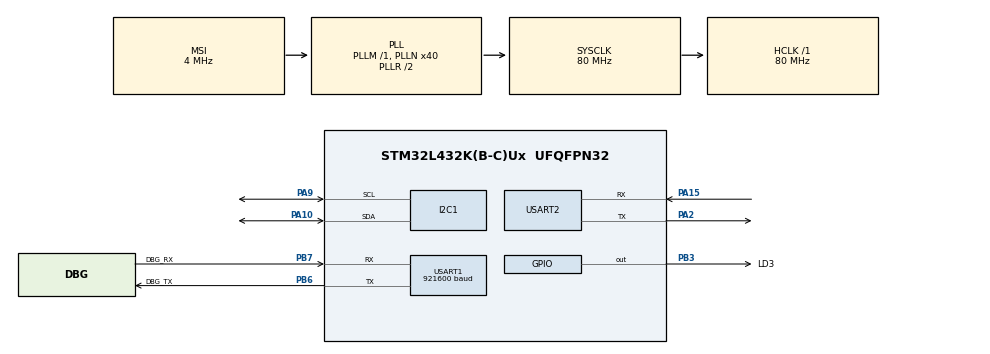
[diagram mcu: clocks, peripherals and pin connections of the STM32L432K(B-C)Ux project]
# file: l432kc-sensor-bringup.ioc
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FREERTOS.Mutexes01=i2c1_mutex,Dynamic,NULL,Available;console_mutex,Dynamic,NULL,Available
FREERTOS.Tasks01=sensorTask,24,512,StartSensorTask,Default,NULL,Dynamic,NULL,NULL;consoleTask,16,256,StartConsoleTask,Default,NULL,Dynamic,NULL,NULL
FREERTOS.configTOTAL_HEAP_SIZE=32768
FREERTOS.configUSE_NEWLIB_REENTRANT=1
I2C1.Timing=0x10909CEC
Mcu.Family=STM32L4
Mcu.Name=STM32L432K(B-C)Ux
Mcu.Package=UFQFPN32
NVIC.I2C1_ER_IRQn=true\:5\:0\:false\:false\:true\:true\:true\:true
NVIC.I2C1_EV_IRQn=true\:5\:0\:false\:false\:true\:true\:true\:true
NVIC.PriorityGroup=NVIC_PRIORITYGROUP_4
NVIC.USART1_IRQn=true\:5\:0\:false\:false\:true\:true\:true\:true
NVIC.USART2_IRQn=true\:5\:0\:false\:false\:true\:true\:true\:true
PA10.Mode=I2C
PA10.Signal=I2C1_SDA
PA15\ (JTDI).Mode=Asynchronous
PA15\ (JTDI).Signal=USART2_RX
PA2.Mode=Asynchronous
PA2.Signal=USART2_TX
PA9.Mode=I2C
PA9.Signal=I2C1_SCL
PB3\ (JTDO-TRACESWO).GPIO_Label=LD3
PB3\ (JTDO-TRACESWO).Signal=GPIO_Output
PB6.GPIO_Label=DBG_TX
PB6.Mode=Asynchronous
PB6.Signal=USART1_TX
PB7.GPIO_Label=DBG_RX
PB7.GPIO_PuPd=GPIO_PULLUP
PB7.Mode=Asynchronous
PB7.Signal=USART1_RX
PC14-OSC32_IN\ (PC14).Mode=LSE-External-Oscillator
PC14-OSC32_IN\ (PC14).Signal=RCC_OSC32_IN
PC15-OSC32_OUT\ (PC15).Mode=LSE-External-Oscillator
PC15-OSC32_OUT\ (PC15).Signal=RCC_OSC32_OUT
ProjectManager.HeapSize=0x200
ProjectManager.StackSize=0x400
ProjectManager.TargetToolchain=STM32CubeIDE
RCC.FLatency=FLASH_LATENCY_4
RCC.HCLKFreq_Value=80000000
RCC.HSE_VALUE=8000000
RCC.HSI48_VALUE=48000000
RCC.HSI_VALUE=16000000
RCC.LSE_VALUE=32768
RCC.MSIPLLMode=RCC_MSIPLL_ENABLE
RCC.MSI_VALUE=4000000
RCC.PLLN=40
RCC.PLLSourceVirtual=RCC_PLLSOURCE_MSI
RCC.SYSCLKFreq_VALUE=80000000
RCC.SYSCLKSource=RCC_SYSCLKSOURCE_PLLCLK
RCC.VCOOutputFreq_Value=32000000
USART1.BaudRate=921600
USART1.VirtualMode-Asynchronous=VM_ASYNC
USART2.VirtualMode-Asynchronous=VM_ASYNC
VP_FREERTOS_VS_CMSIS_V2.Mode=CMSIS_V2
board=custom

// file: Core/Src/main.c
/* USER CODE BEGIN Header */
/**
  ******************************************************************************
  * @file           : main.c
  * @brief          : Main program body
  *
  *  The application (BMP390 and SHT31 bring-up) is in app.cpp; this file
  *  stays CubeMX's, and its USER CODE blocks only call into app.h.
  ******************************************************************************
  * @attention
  *
  * Copyright (c) 2026 STMicroelectronics.
  * All rights reserved.
  *
  * This software is licensed under terms that can be found in the LICENSE file
  * in the root directory of this software component.
  * If no LICENSE file comes with this software, it is provided AS-IS.
  *
  ******************************************************************************
  */
/* USER CODE END Header */
#include "main.h"
#include "cmsis_os.h"

/* USER CODE BEGIN Includes */
#include "app.h"
/* USER CODE END Includes */

I2C_HandleTypeDef hi2c1;

UART_HandleTypeDef huart1;
UART_HandleTypeDef huart2;

/* Definitions for sensorTask */
osThreadId_t sensorTaskHandle;
const osThreadAttr_t sensorTask_attributes = {
  .name = "sensorTask",
  .stack_size = 512 * 4,
  .priority = (osPriority_t) osPriorityNormal,
};
/* Definitions for consoleTask */
osThreadId_t consoleTaskHandle;
const osThreadAttr_t consoleTask_attributes = {
  .name = "consoleTask",
  .stack_size = 256 * 4,
  .priority = (osPriority_t) osPriorityBelowNormal,
};
/* Definitions for i2c1_mutex */
osMutexId_t i2c1_mutexHandle;
const osMutexAttr_t i2c1_mutex_attributes = {
  .name = "i2c1_mutex"
};
/* Definitions for console_mutex */
osMutexId_t console_mutexHandle;
const osMutexAttr_t console_mutex_attributes = {
  .name = "console_mutex"
};

void SystemClock_Config(void);
static void MX_GPIO_Init(void);
static void MX_I2C1_Init(void);
static void MX_USART1_UART_Init(void);
static void MX_USART2_UART_Init(void);
void StartSensorTask(void *argument);
void StartConsoleTask(void *argument);

int main(void)
{

  /* MCU Configuration--------------------------------------------------------*/

  /* Reset of all peripherals, Initializes the Flash interface and the Systick. */
  HAL_Init();

  /* Configure the system clock */
  SystemClock_Config();

  /* Initialize all configured peripherals */
  MX_GPIO_Init();
  MX_I2C1_Init();
  MX_USART1_UART_Init();
  MX_USART2_UART_Init();
  /* USER CODE BEGIN 2 */
  app_init();
  /* USER CODE END 2 */

  /* Init scheduler */
  osKernelInitialize();
  /* Create the mutex(es) */
  /* creation of i2c1_mutex */
  i2c1_mutexHandle = osMutexNew(&i2c1_mutex_attributes);

  /* creation of console_mutex */
  console_mutexHandle = osMutexNew(&console_mutex_attributes);

  /* Create the thread(s) */
  /* creation of sensorTask */
  sensorTaskHandle = osThreadNew(StartSensorTask, NULL, &sensorTask_attributes);

  /* creation of consoleTask */
  consoleTaskHandle = osThreadNew(StartConsoleTask, NULL, &consoleTask_attributes);

  /* Start scheduler */
  osKernelStart();

  /* We should never get here as control is now taken by the scheduler */

  /* Infinite loop */
  while (1)
  {

  }
}

void SystemClock_Config(void)
{
  RCC_OscInitTypeDef RCC_OscInitStruct = {0};
  RCC_ClkInitTypeDef RCC_ClkInitStruct = {0};

  /** Configure the main internal regulator output voltage
  */
  if (HAL_PWREx_ControlVoltageScaling(PWR_REGULATOR_VOLTAGE_SCALE1) != HAL_OK)
  {
    Error_Handler();
  }

  /** Configure LSE Drive Capability
  */
  HAL_PWR_EnableBkUpAccess();
  __HAL_RCC_LSEDRIVE_CONFIG(RCC_LSEDRIVE_LOW);

  /** Initializes the RCC Oscillators according to the specified parameters
  * in the RCC_OscInitTypeDef structure.
  * MSI 4 MHz -> PLL x40 /2 -> 80 MHz; the LSE crystal (X2) trims the MSI.
  */
  RCC_OscInitStruct.OscillatorType = RCC_OSCILLATORTYPE_LSE|RCC_OSCILLATORTYPE_MSI;
  RCC_OscInitStruct.LSEState = RCC_LSE_ON;
  RCC_OscInitStruct.MSIState = RCC_MSI_ON;
  RCC_OscInitStruct.MSICalibrationValue = 0;
  RCC_OscInitStruct.MSIClockRange = RCC_MSIRANGE_6;
  RCC_OscInitStruct.PLL.PLLState = RCC_PLL_ON;
  RCC_OscInitStruct.PLL.PLLSource = RCC_PLLSOURCE_MSI;
  RCC_OscInitStruct.PLL.PLLM = 1;
  RCC_OscInitStruct.PLL.PLLN = 40;
  RCC_OscInitStruct.PLL.PLLP = RCC_PLLP_DIV7;
  RCC_OscInitStruct.PLL.PLLQ = RCC_PLLQ_DIV2;
  RCC_OscInitStruct.PLL.PLLR = RCC_PLLR_DIV2;
  if (HAL_RCC_OscConfig(&RCC_OscInitStruct) != HAL_OK)
  {
    Error_Handler();
  }

  /** Initializes the CPU, AHB and APB buses clocks
  */
  RCC_ClkInitStruct.ClockType = RCC_CLOCKTYPE_HCLK|RCC_CLOCKTYPE_SYSCLK
                              |RCC_CLOCKTYPE_PCLK1|RCC_CLOCKTYPE_PCLK2;
  RCC_ClkInitStruct.SYSCLKSource = RCC_SYSCLKSOURCE_PLLCLK;
  RCC_ClkInitStruct.AHBCLKDivider = RCC_SYSCLK_DIV1;
  RCC_ClkInitStruct.APB1CLKDivider = RCC_HCLK_DIV1;
  RCC_ClkInitStruct.APB2CLKDivider = RCC_HCLK_DIV1;

  if (HAL_RCC_ClockConfig(&RCC_ClkInitStruct, FLASH_LATENCY_4) != HAL_OK)
  {
    Error_Handler();
  }

  /** Enable MSI Auto calibration
  */
  HAL_RCCEx_EnableMSIPLLMode();
}

static void MX_I2C1_Init(void)
{

  hi2c1.Instance = I2C1;
  hi2c1.Init.Timing = 0x10909CEC;   // 100 kHz (standard mode) at 80 MHz; the BMP390 and SHT31 also take 400 kHz
  hi2c1.Init.OwnAddress1 = 0;
  hi2c1.Init.AddressingMode = I2C_ADDRESSINGMODE_7BIT;
  hi2c1.Init.DualAddressMode = I2C_DUALADDRESS_DISABLE;
  hi2c1.Init.OwnAddress2 = 0;
  hi2c1.Init.OwnAddress2Masks = I2C_OA2_NOMASK;
  hi2c1.Init.GeneralCallMode = I2C_GENERALCALL_DISABLE;
  hi2c1.Init.NoStretchMode = I2C_NOSTRETCH_DISABLE;
  if (HAL_I2C_Init(&hi2c1) != HAL_OK)
  {
    Error_Handler();
  }

  /** Configure Analogue filter
  */
  if (HAL_I2CEx_ConfigAnalogFilter(&hi2c1, I2C_ANALOGFILTER_ENABLE) != HAL_OK)
  {
    Error_Handler();
  }

  /** Configure Digital filter
  */
  if (HAL_I2CEx_ConfigDigitalFilter(&hi2c1, 0) != HAL_OK)
  {
    Error_Handler();
  }

}

static void MX_USART1_UART_Init(void)
{

  huart1.Instance = USART1;
  huart1.Init.BaudRate = 921600;
  huart1.Init.WordLength = UART_WORDLENGTH_8B;
  huart1.Init.StopBits = UART_STOPBITS_1;
  huart1.Init.Parity = UART_PARITY_NONE;
  huart1.Init.Mode = UART_MODE_TX_RX;
  huart1.Init.HwFlowCtl = UART_HWCONTROL_NONE;
  huart1.Init.OverSampling = UART_OVERSAMPLING_16;
  huart1.Init.OneBitSampling = UART_ONE_BIT_SAMPLE_DISABLE;
  huart1.AdvancedInit.AdvFeatureInit = UART_ADVFEATURE_NO_INIT;
  if (HAL_UART_Init(&huart1) != HAL_OK)
  {
    Error_Handler();
  }

}

static void MX_USART2_UART_Init(void)
{

  huart2.Instance = USART2;
  huart2.Init.BaudRate = 115200;
  huart2.Init.WordLength = UART_WORDLENGTH_8B;
  huart2.Init.StopBits = UART_STOPBITS_1;
  huart2.Init.Parity = UART_PARITY_NONE;
  huart2.Init.Mode = UART_MODE_TX_RX;
  huart2.Init.HwFlowCtl = UART_HWCONTROL_NONE;
  huart2.Init.OverSampling = UART_OVERSAMPLING_16;
  huart2.Init.OneBitSampling = UART_ONE_BIT_SAMPLE_DISABLE;
  huart2.AdvancedInit.AdvFeatureInit = UART_ADVFEATURE_NO_INIT;
  if (HAL_UART_Init(&huart2) != HAL_OK)
  {
    Error_Handler();
  }

}

static void MX_GPIO_Init(void)
{
  GPIO_InitTypeDef GPIO_InitStruct = {0};

  /* GPIO Ports Clock Enable */
  __HAL_RCC_GPIOC_CLK_ENABLE();
  __HAL_RCC_GPIOA_CLK_ENABLE();
  __HAL_RCC_GPIOB_CLK_ENABLE();

  /*Configure GPIO pin Output Level */
  HAL_GPIO_WritePin(LD3_GPIO_Port, LD3_Pin, GPIO_PIN_RESET);

  /*Configure GPIO pin : LD3_Pin */
  GPIO_InitStruct.Pin = LD3_Pin;
  GPIO_InitStruct.Mode = GPIO_MODE_OUTPUT_PP;
  GPIO_InitStruct.Pull = GPIO_NOPULL;
  GPIO_InitStruct.Speed = GPIO_SPEED_FREQ_LOW;
  HAL_GPIO_Init(LD3_GPIO_Port, &GPIO_InitStruct);

}

void StartSensorTask(void *argument)
{
  /* USER CODE BEGIN 5 */
  app_sensor_task(argument);
  /* USER CODE END 5 */
}

void StartConsoleTask(void *argument)
{
  /* USER CODE BEGIN StartConsoleTask */
  app_console_task(argument);
  /* USER CODE END StartConsoleTask */
}

void Error_Handler(void)
{
  __disable_irq();
  while (1)
  {
  }
}
